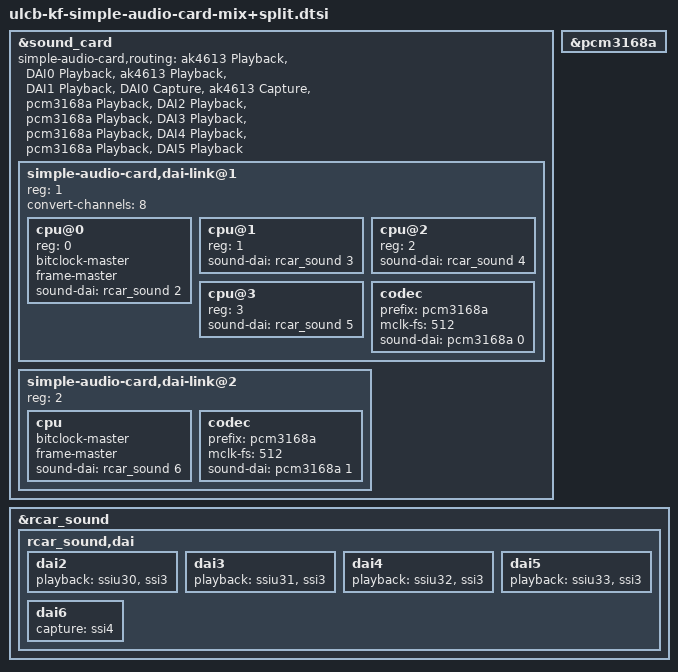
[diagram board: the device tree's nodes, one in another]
&sound_card {
	simple-audio-card,routing = "ak4613 Playback",   "DAI0 Playback",
				    "ak4613 Playback",   "DAI1 Playback",
				    "DAI0 Capture",      "ak4613 Capture",
				    "pcm3168a Playback", "DAI2 Playback",
				    "pcm3168a Playback", "DAI3 Playback",
				    "pcm3168a Playback", "DAI4 Playback",
				    "pcm3168a Playback", "DAI5 Playback";
	simple-audio-card,dai-link@1 {
		#address-cells = <1>;
		#size-cells = <0>;
		reg = <1>;
		convert-channels = <8>;  
		cpu@0 {
			reg = <0>;
			bitclock-master;
			frame-master;
			sound-dai = <&rcar_sound 2>;
		};
		cpu@1 {
			reg = <1>;
			sound-dai = <&rcar_sound 3>;
		};
		cpu@2 {
			reg = <2>;
			sound-dai = <&rcar_sound 4>;
		};
		cpu@3 {
			reg = <3>;
			sound-dai = <&rcar_sound 5>;
		};
		codec {
			prefix = "pcm3168a";
			mclk-fs = <512>;
			sound-dai = <&pcm3168a 0>;
		};
	};
	simple-audio-card,dai-link@2 {
		reg = <2>;
		cpu {
			bitclock-master;
			frame-master;
			sound-dai = <&rcar_sound 6>;
		};
		codec {
			prefix = "pcm3168a";
			mclk-fs = <512>;
			sound-dai = <&pcm3168a 1>;
		};
	};
};
&pcm3168a {
	#sound-dai-cells = <1>;
};
&rcar_sound {
	rcar_sound,dai {
		dai2 {
			playback = <&ssiu30 &ssi3>;
		};
		dai3 {
			playback = <&ssiu31 &ssi3>;
		};
		dai4 {
			playback = <&ssiu32 &ssi3>;
		};
		dai5 {
			playback = <&ssiu33 &ssi3>;
		};
		dai6 {
			capture = <&ssi4>;
		};
	};
};
